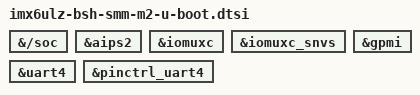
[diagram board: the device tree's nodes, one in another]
// SPDX-License-Identifier: GPL-2.0
/*
 * Copyright (C) 2022 BSH Hausgeraete GmbH
 *
 * Author: Michael Trimarchi <michael@amarulasolutions.com>
 */

&{/soc} {
	u-boot,dm-all;
};

&aips2 {
	u-boot,dm-all;
};

&iomuxc {
	u-boot,dm-all;
};

&iomuxc_snvs {
	u-boot,dm-all;
};

&uart4 {
	u-boot,dm-all;
};

&pinctrl_uart4 {
	u-boot,dm-all;
};

&gpmi {
	u-boot,dm-spl;
	u-boot,dm-all;
};
